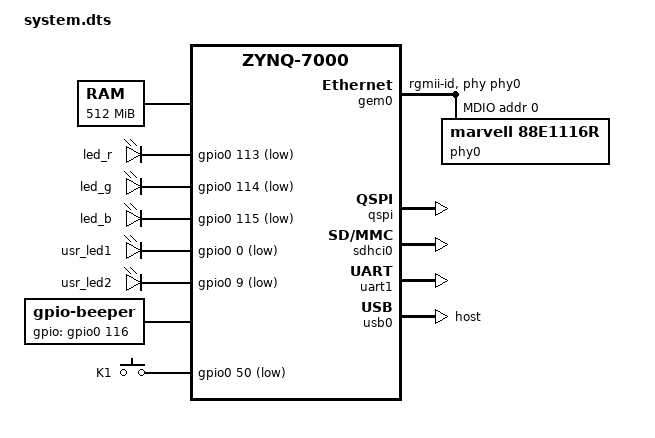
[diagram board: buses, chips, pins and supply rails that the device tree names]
/*
 * CAUTION: This file is automatically generated by Xilinx.
 * Version:  
 * Today is: Tue May 15 12:30:16 2018
 */


/dts-v1/;
/include/ "zynq-7000.dtsi"
/include/ "pl.dtsi"
/ {
	cpus {
		cpu@0 {
			operating-points = <666666 1000000 333333 1000000>;
		};
	};
	chosen {
		bootargs = "console=ttyPS0,115200 root=/dev/mmcblk0p2 rw earlyprintk rootfstype=ext4 rootwait devtmpfs.mount=1";
	};
	aliases {
		ethernet0 = &gem0;
		serial0 = &uart1;
		spi0 = &qspi;
	};
	memory {
		device_type = "memory";
		reg = <0x0 0x20000000>;
	};
};
&gem0 {
	local-mac-address = [00 0a 35 00 00 00];
	phy-handle = <&phy0>;
	phy-mode = "rgmii-id";
	status = "okay";
	xlnx,ptp-enet-clock = <0x69f6bcb>;
	ps7_ethernet_0_mdio: mdio {
		#address-cells = <1>;
		#size-cells = <0>;
                phy0: phy@0 {
                   compatible = "marvell,88e1116r";
                   device_type = "ethernet-phy";
                   reg = <0>;
                } ;
	};
};
&gpio0 {
	emio-gpio-width = <22>;
	gpio-mask-high = <0x0>;
	gpio-mask-low = <0x5600>;
};
&intc {
	num_cpus = <2>;
	num_interrupts = <96>;
};
&qspi {
	is-dual = <0>;
	num-cs = <1>;
	status = "okay";
};
&sdhci0 {
	status = "okay";
	xlnx,has-cd = <0x1>;
	xlnx,has-power = <0x0>;
	xlnx,has-wp = <0x1>;
};
&uart1 {
	device_type = "serial";
	port-number = <0>;
	status = "okay";
};
&usb0 {
	dr_mode = "host";
	phy_type = "ulpi";
	status = "okay";
};
&clkc {
	fclk-enable = <0x1>;
	ps-clk-frequency = <33333333>;
};

/ {
    leds {
        compatible = "gpio-leds";

        led_r {
	        label = "led_r";
            /*
             * 54+(Gpio)59=113
             */
		    gpios = <&gpio0 113 1>;
		    default-state = "on";
		    linux,default-trigger = "heartbeat";
	    };

	    led_g {
		    label = "led_g";
            /*
             * 54+(Gpio)60=114
            */
		    gpios = <&gpio0 114 1>;
		    default-state = "on";
		    linux,default-trigger = "heartbeat";
	    };

	    led_b {
		    label = "led_b";
            /*
             * 54+(Gpio)61=115
             */
		    gpios = <&gpio0 115 1>;
		    default-state = "on";
		    linux,default-trigger = "heartbeat";
	    };

	    usr_led1 {
		    label = "usr_led1";
            /*
             * MIO0
             */
		    gpios = <&gpio0 0 1>;
    	    default-state = "off";
		    linux,default-trigger = "none";
	    };

	    usr_led2 {
		    label = "usr_led2";
            /*
             * MIO9
             */
		    gpios = <&gpio0 9 1>;
		    default-state = "off";
		    linux,default-trigger = "none";
	    };
    };

        gpio-beep {
	        compatible = "gpio-beeper";
	        lable = "pl-beep";
            /*
             * 54+(Gpio)62=116
             */
	        gpios = <&gpio0 116 0>;
        };

        gpio-keys {
	        compatible = "gpio-keys";
	        #address-cells = <0x1>;
	        #size-cells = <0x0>;
	        autorepeat;

	        K1 {
		        label = "K1";
				/*
				 * MIO50
                 */
		        gpios = <&gpio0 50 1>;
		        linux,code = <0x66>;
		        gpio-key,wakeup;
		        autorepeat;
	        };
        };
};
